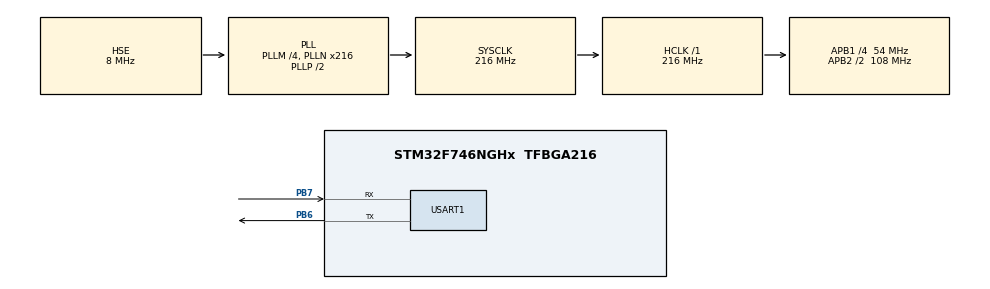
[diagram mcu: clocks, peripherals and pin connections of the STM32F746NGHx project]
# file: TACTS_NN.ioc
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CORTEX_M7.ART_ACCELERATOR_ENABLE=0
CORTEX_M7.CPU_DCache=Enabled
CORTEX_M7.CPU_ICache=Enabled
CORTEX_M7.PREFETCH_ENABLE=0
Mcu.Family=STM32F7
Mcu.Name=STM32F746NGHx
Mcu.Package=TFBGA216
NVIC.PriorityGroup=NVIC_PRIORITYGROUP_4
NVIC.RCC_IRQn=true\:0\:0\:false\:true\:true\:3\:true\:false\:true
NVIC.TIM7_IRQn=true\:0\:0\:false\:true\:true\:1\:true\:true\:true
NVIC.USART1_IRQn=true\:0\:0\:false\:true\:true\:2\:true\:true\:true
PB6.Mode=Asynchronous
PB6.Signal=USART1_TX
PB7.Mode=Asynchronous
PB7.Signal=USART1_RX
PH0/OSC_IN.Mode=HSE-External-Clock-Source
PH0/OSC_IN.Signal=RCC_OSC_IN
PH1/OSC_OUT.Mode=HSE-External-Clock-Source
PH1/OSC_OUT.Signal=RCC_OSC_OUT
ProjectManager.HeapSize=0x800
ProjectManager.StackSize=0x800
ProjectManager.TargetToolchain=STM32CubeIDE
RCC.AHBFreq_Value=216000000
RCC.APB1CLKDivider=RCC_HCLK_DIV4
RCC.APB1Freq_Value=54000000
RCC.APB1TimFreq_Value=108000000
RCC.APB2CLKDivider=RCC_HCLK_DIV2
RCC.APB2Freq_Value=108000000
RCC.APB2TimFreq_Value=216000000
RCC.CortexFreq_Value=216000000
RCC.HCLKFreq_Value=216000000
RCC.HSE_VALUE=8000000
RCC.HSI_VALUE=16000000
RCC.LSE_VALUE=32768
RCC.PLLM=4
RCC.PLLN=216
RCC.PLLSourceVirtual=RCC_PLLSOURCE_HSE
RCC.SYSCLKFreq_VALUE=216000000
RCC.SYSCLKSource=RCC_SYSCLKSOURCE_PLLCLK
RCC.USBFreq_Value=216000000
RCC.VCOOutputFreq_Value=432000000
STMicroelectronics.X-CUBE-AI.7.3.0.ActivationBufferSizeList=2568
STMicroelectronics.X-CUBE-AI.7.3.0.ActivationBuffers=pool0
STMicroelectronics.X-CUBE-AI.7.3.0.ActivationNames=pool0
STMicroelectronics.X-CUBE-AI.7.3.0.ActivationSizes=AI_SINE_MODEL_DATA_ACTIVATION_1_SIZE
STMicroelectronics.X-CUBE-AI.7.3.0.HeapSize=0x800
STMicroelectronics.X-CUBE-AI.7.3.0.InternalRamActivationBufferMaxSize=AI_SINE_MODEL_DATA_ACTIVATIONS_SIZE
STMicroelectronics.X-CUBE-AI.7.3.0.LatestDirectoryUsed-a62f4d3bafe6ca32647149b166fa59e7c2f2bd1009ed74961086bef699054160=D\:\\ME program\\2017-PhD\\01_research\\02Study\\34_ballon_like_cover\\DeepLearing\\TACTS\\TensorflowLite
STMicroelectronics.X-CUBE-AI.7.3.0.MaximumNumberOfInputLayer=1
STMicroelectronics.X-CUBE-AI.7.3.0.MaximumNumberOfOutputLayer=1
STMicroelectronics.X-CUBE-AI.7.3.0.MaximumSizeOfInputLayer=1
STMicroelectronics.X-CUBE-AI.7.3.0.MaximumSizeOfOutputLayer=1
STMicroelectronics.X-CUBE-AI.7.3.0.ModelActualCompression-a62f4d3bafe6ca32647149b166fa59e7c2f2bd1009ed74961086bef699054160=0.0
STMicroelectronics.X-CUBE-AI.7.3.0.ModelCompression-a62f4d3bafe6ca32647149b166fa59e7c2f2bd1009ed74961086bef699054160=None
STMicroelectronics.X-CUBE-AI.7.3.0.ModelFlashOccupation-a62f4d3bafe6ca32647149b166fa59e7c2f2bd1009ed74961086bef699054160=17012
STMicroelectronics.X-CUBE-AI.7.3.0.ModelHashList=a62f4d3bafe6ca32647149b166fa59e7c2f2bd1009ed74961086bef699054160
STMicroelectronics.X-CUBE-AI.7.3.0.ModelKind-a62f4d3bafe6ca32647149b166fa59e7c2f2bd1009ed74961086bef699054160=TFLITE
STMicroelectronics.X-CUBE-AI.7.3.0.ModelMacc-a62f4d3bafe6ca32647149b166fa59e7c2f2bd1009ed74961086bef699054160=641
STMicroelectronics.X-CUBE-AI.7.3.0.ModelName-a62f4d3bafe6ca32647149b166fa59e7c2f2bd1009ed74961086bef699054160=sine_model
STMicroelectronics.X-CUBE-AI.7.3.0.ModelNameList=sine_model
STMicroelectronics.X-CUBE-AI.7.3.0.ModelRamOccupation-a62f4d3bafe6ca32647149b166fa59e7c2f2bd1009ed74961086bef699054160=2568
STMicroelectronics.X-CUBE-AI.7.3.0.ModelStructureFile-a62f4d3bafe6ca32647149b166fa59e7c2f2bd1009ed74961086bef699054160=D\:\\ME program\\2017-PhD\\01_research\\02Study\\34_ballon_like_cover\\DeepLearing\\TACTS\\TensorflowLite\\sine_model.tflite
STMicroelectronics.X-CUBE-AI.7.3.0.ModelType-a62f4d3bafe6ca32647149b166fa59e7c2f2bd1009ed74961086bef699054160=STM32Cube.AI runtime
STMicroelectronics.X-CUBE-AI.7.3.0.ReadyForCodeGeneration=true
STMicroelectronics.X-CUBE-AI.7.3.0.StackSize=0x800
STMicroelectronics.X-CUBE-AI.7.3.0.WorkingBufferStartAddrList=0xFFFFFFFF
STMicroelectronics.X-CUBE-AI.7.3.0.XAaCUBEAaAICcArtificialOoIntelligenceJjCore=true
STMicroelectronics.X-CUBE-AI.7.3.0.copyWeightToRam=false
STMicroelectronics.X-CUBE-AI.7.3.0.copyWeightToRam-a62f4d3bafe6ca32647149b166fa59e7c2f2bd1009ed74961086bef699054160=false
STMicroelectronics.X-CUBE-AI.7.3.0.customLayerConfigEnabled=false
STMicroelectronics.X-CUBE-AI.7.3.0.customLayerConfigEnabled-a62f4d3bafe6ca32647149b166fa59e7c2f2bd1009ed74961086bef699054160=false
STMicroelectronics.X-CUBE-AI.7.3.0.useInputAllocation=true
STMicroelectronics.X-CUBE-AI.7.3.0.useInputAllocation-a62f4d3bafe6ca32647149b166fa59e7c2f2bd1009ed74961086bef699054160=true
STMicroelectronics.X-CUBE-AI.7.3.0.useOutputAllocation=true
STMicroelectronics.X-CUBE-AI.7.3.0.useOutputAllocation-a62f4d3bafe6ca32647149b166fa59e7c2f2bd1009ed74961086bef699054160=true
TIM7.Prescaler=216-1
USART1.VirtualMode-Asynchronous=VM_ASYNC
VP_CRC_VS_CRC.Mode=CRC_Activate
VP_STMicroelectronics.X-CUBE-AI_VS_ArtificialOoIntelligenceJjXAaCUBEAaAI_7.3.0.Mode=ArtificialOoIntelligenceJjXAaCUBEAaAI
VP_TIM7_VS_ClockSourceINT.Mode=Enable_Timer
board=custom

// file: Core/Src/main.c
/* USER CODE BEGIN Header */
/**
  ******************************************************************************
  * @file           : main.c
  * @brief          : Main program body
  ******************************************************************************
  * @attention
  *
  * Copyright (c) 2023 STMicroelectronics.
  * All rights reserved.
  *
  * This software is licensed under terms that can be found in the LICENSE file
  * in the root directory of this software component.
  * If no LICENSE file comes with this software, it is provided AS-IS.
  *
  ******************************************************************************
  */
/* USER CODE END Header */
#include "main.h"

/* USER CODE BEGIN Includes */
#include <stdio.h>

#include "ai_datatypes_defines.h"
#include "ai_platform.h"
#include "sine_model.h"
#include "sine_model_data.h"
#include <string.h>
/* USER CODE END Includes */

/* USER CODE BEGIN PTD */

#define PI 3.14159

/* USER CODE END PTD */

CRC_HandleTypeDef hcrc;

TIM_HandleTypeDef htim7;

UART_HandleTypeDef huart1;

void SystemClock_Config(void);
static void MX_GPIO_Init(void);
static void MX_CRC_Init(void);
static void MX_TIM7_Init(void);
static void MX_USART1_UART_Init(void);
static void MX_NVIC_Init(void);

int main(void)
{
  /* USER CODE BEGIN 1 */

	char buf[50];
	int buf_len = 0;
	uint8_t timestamp = 0;

	// Chunk of memory used to hold intermediate values for neural network
	AI_ALIGNED(4) ai_u8 activations[AI_SINE_MODEL_DATA_ACTIVATIONS_SIZE];

	// Buffers used to store input and output tensors
	AI_ALIGNED(4) ai_i8 in_data[AI_SINE_MODEL_IN_1_SIZE_BYTES];
	AI_ALIGNED(4) ai_i8 out_data[AI_SINE_MODEL_OUT_1_SIZE_BYTES];

	ai_handle sine_model = AI_HANDLE_NULL;

	ai_buffer ai_input[AI_SINE_MODEL_IN_NUM];
	ai_buffer ai_output[AI_SINE_MODEL_OUT_NUM];

	ai_network_params ai_params = {
	AI_SINE_MODEL_DATA_WEIGHTS(ai_sine_model_data_weights_get()),
	AI_SINE_MODEL_DATA_ACTIVATIONS(activations)
	};
	ai_input[0].data = AI_HANDLE_PTR(in_data);
	ai_output[0].data = AI_HANDLE_PTR(out_data);

  /* USER CODE END 1 */

  /* Enable I-Cache---------------------------------------------------------*/
  SCB_EnableICache();

  /* Enable D-Cache---------------------------------------------------------*/
  SCB_EnableDCache();

  /* MCU Configuration--------------------------------------------------------*/

  /* Reset of all peripherals, Initializes the Flash interface and the Systick. */
  HAL_Init();

  /* Configure the system clock */
  SystemClock_Config();

  /* Initialize all configured peripherals */
  MX_GPIO_Init();
  MX_CRC_Init();
  MX_TIM7_Init();
  MX_USART1_UART_Init();

  /* Initialize interrupts */
  MX_NVIC_Init();
  /* USER CODE BEGIN 2 */

  buf_len = sprintf(buf, "\r\n\r\nSTM32 X-Cube-AI test!!!!!!!!!!\r\n");
  HAL_UART_Transmit(&huart1, (uint8_t *)buf, buf_len, 100);

  HAL_TIM_Base_Start(&htim7);

  // Greetings!
  buf_len = sprintf(buf, "\r\n\r\nSTM32 X-Cube-AI test\r\n");
  HAL_UART_Transmit(&huart1, (uint8_t *)buf, buf_len, 100);

  float input = 0.5f;  // ?���? ?��?�� Sine ?��?��?�� ?��?��
  float output = 0.0f;  // 모델?�� 계산?�� 출력?�� ???��?�� �??��

  /* USER CODE END 2 */

  /* Infinite loop */
  /* USER CODE BEGIN WHILE */
  while (1)
  {
	  // Fill input buffer (use test value)
	     // Get current timestamp
	       ai_sine_model_run(sine_model, &ai_input[0], &ai_output[0]);
	       // Print output of neural network along with inference time (microseconds)
	       HAL_UART_Transmit(&huart1, (uint8_t *)buf, sprintf(buf,"Output: %f | Duration: %lu\r\n", output, htim7.Instance->CNT - timestamp), 100);
	       HAL_Delay(100);

	     // Wait before doing it again

    /* USER CODE END WHILE */

  }
}

void SystemClock_Config(void)
{
  RCC_OscInitTypeDef RCC_OscInitStruct = {0};
  RCC_ClkInitTypeDef RCC_ClkInitStruct = {0};

  /** Configure the main internal regulator output voltage
  */
  __HAL_RCC_PWR_CLK_ENABLE();
  __HAL_PWR_VOLTAGESCALING_CONFIG(PWR_REGULATOR_VOLTAGE_SCALE1);

  /** Initializes the RCC Oscillators according to the specified parameters
  * in the RCC_OscInitTypeDef structure.
  */
  RCC_OscInitStruct.OscillatorType = RCC_OSCILLATORTYPE_HSE;
  RCC_OscInitStruct.HSEState = RCC_HSE_BYPASS;
  RCC_OscInitStruct.PLL.PLLState = RCC_PLL_ON;
  RCC_OscInitStruct.PLL.PLLSource = RCC_PLLSOURCE_HSE;
  RCC_OscInitStruct.PLL.PLLM = 4;
  RCC_OscInitStruct.PLL.PLLN = 216;
  RCC_OscInitStruct.PLL.PLLP = RCC_PLLP_DIV2;
  RCC_OscInitStruct.PLL.PLLQ = 2;
  if (HAL_RCC_OscConfig(&RCC_OscInitStruct) != HAL_OK)
  {
    Error_Handler();
  }

  /** Activate the Over-Drive mode
  */
  if (HAL_PWREx_EnableOverDrive() != HAL_OK)
  {
    Error_Handler();
  }

  /** Initializes the CPU, AHB and APB buses clocks
  */
  RCC_ClkInitStruct.ClockType = RCC_CLOCKTYPE_HCLK|RCC_CLOCKTYPE_SYSCLK
                              |RCC_CLOCKTYPE_PCLK1|RCC_CLOCKTYPE_PCLK2;
  RCC_ClkInitStruct.SYSCLKSource = RCC_SYSCLKSOURCE_PLLCLK;
  RCC_ClkInitStruct.AHBCLKDivider = RCC_SYSCLK_DIV1;
  RCC_ClkInitStruct.APB1CLKDivider = RCC_HCLK_DIV4;
  RCC_ClkInitStruct.APB2CLKDivider = RCC_HCLK_DIV2;

  if (HAL_RCC_ClockConfig(&RCC_ClkInitStruct, FLASH_LATENCY_7) != HAL_OK)
  {
    Error_Handler();
  }
}

/**
  * @brief NVIC Configuration.
  * @retval None
  */
static void MX_NVIC_Init(void)
{
  /* TIM7_IRQn interrupt configuration */
  HAL_NVIC_SetPriority(TIM7_IRQn, 0, 0);
  HAL_NVIC_EnableIRQ(TIM7_IRQn);
  /* USART1_IRQn interrupt configuration */
  HAL_NVIC_SetPriority(USART1_IRQn, 0, 0);
  HAL_NVIC_EnableIRQ(USART1_IRQn);
  /* RCC_IRQn interrupt configuration */
  HAL_NVIC_SetPriority(RCC_IRQn, 0, 0);
  HAL_NVIC_EnableIRQ(RCC_IRQn);
}

static void MX_CRC_Init(void)
{

  hcrc.Instance = CRC;
  hcrc.Init.DefaultPolynomialUse = DEFAULT_POLYNOMIAL_ENABLE;
  hcrc.Init.DefaultInitValueUse = DEFAULT_INIT_VALUE_ENABLE;
  hcrc.Init.InputDataInversionMode = CRC_INPUTDATA_INVERSION_NONE;
  hcrc.Init.OutputDataInversionMode = CRC_OUTPUTDATA_INVERSION_DISABLE;
  hcrc.InputDataFormat = CRC_INPUTDATA_FORMAT_BYTES;
  if (HAL_CRC_Init(&hcrc) != HAL_OK)
  {
    Error_Handler();
  }

}

static void MX_TIM7_Init(void)
{

  TIM_MasterConfigTypeDef sMasterConfig = {0};

  htim7.Instance = TIM7;
  htim7.Init.Prescaler = 216-1;
  htim7.Init.CounterMode = TIM_COUNTERMODE_UP;
  htim7.Init.Period = 65535;
  htim7.Init.AutoReloadPreload = TIM_AUTORELOAD_PRELOAD_DISABLE;
  if (HAL_TIM_Base_Init(&htim7) != HAL_OK)
  {
    Error_Handler();
  }
  sMasterConfig.MasterOutputTrigger = TIM_TRGO_RESET;
  sMasterConfig.MasterSlaveMode = TIM_MASTERSLAVEMODE_DISABLE;
  if (HAL_TIMEx_MasterConfigSynchronization(&htim7, &sMasterConfig) != HAL_OK)
  {
    Error_Handler();
  }

}

static void MX_USART1_UART_Init(void)
{

  huart1.Instance = USART1;
  huart1.Init.BaudRate = 115200;
  huart1.Init.WordLength = UART_WORDLENGTH_8B;
  huart1.Init.StopBits = UART_STOPBITS_1;
  huart1.Init.Parity = UART_PARITY_NONE;
  huart1.Init.Mode = UART_MODE_TX_RX;
  huart1.Init.HwFlowCtl = UART_HWCONTROL_NONE;
  huart1.Init.OverSampling = UART_OVERSAMPLING_16;
  huart1.Init.OneBitSampling = UART_ONE_BIT_SAMPLE_DISABLE;
  huart1.AdvancedInit.AdvFeatureInit = UART_ADVFEATURE_NO_INIT;
  if (HAL_UART_Init(&huart1) != HAL_OK)
  {
    Error_Handler();
  }

}

static void MX_GPIO_Init(void)
{

  /* GPIO Ports Clock Enable */
  __HAL_RCC_GPIOB_CLK_ENABLE();
  __HAL_RCC_GPIOH_CLK_ENABLE();

}

void Error_Handler(void)
{
  __disable_irq();
  while (1)
  {
  }
}
